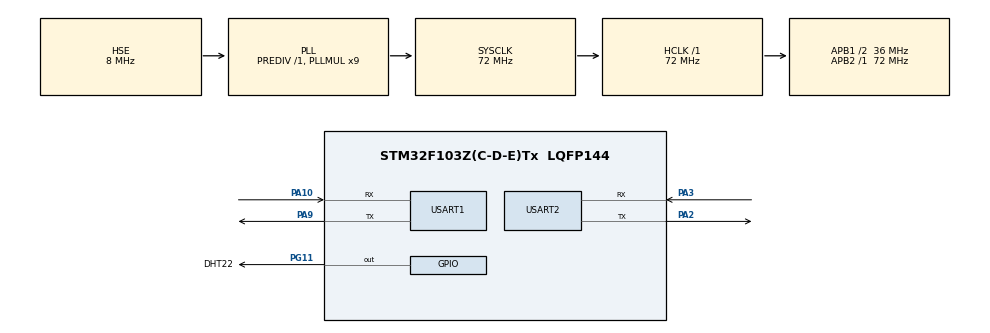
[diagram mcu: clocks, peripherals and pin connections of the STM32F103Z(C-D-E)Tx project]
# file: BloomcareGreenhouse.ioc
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Dma.Request0=USART2_RX
Dma.Request1=USART2_TX
Dma.USART2_RX.0.Direction=DMA_PERIPH_TO_MEMORY
Dma.USART2_RX.0.Instance=DMA1_Channel6
Dma.USART2_RX.0.MemDataAlignment=DMA_MDATAALIGN_BYTE
Dma.USART2_RX.0.MemInc=DMA_MINC_ENABLE
Dma.USART2_RX.0.Mode=DMA_CIRCULAR
Dma.USART2_RX.0.PeriphDataAlignment=DMA_PDATAALIGN_BYTE
Dma.USART2_RX.0.PeriphInc=DMA_PINC_DISABLE
Dma.USART2_RX.0.Priority=DMA_PRIORITY_LOW
Dma.USART2_TX.1.Direction=DMA_MEMORY_TO_PERIPH
Dma.USART2_TX.1.Instance=DMA1_Channel7
Dma.USART2_TX.1.MemDataAlignment=DMA_MDATAALIGN_BYTE
Dma.USART2_TX.1.MemInc=DMA_MINC_ENABLE
Dma.USART2_TX.1.Mode=DMA_NORMAL
Dma.USART2_TX.1.PeriphDataAlignment=DMA_PDATAALIGN_BYTE
Dma.USART2_TX.1.PeriphInc=DMA_PINC_DISABLE
Dma.USART2_TX.1.Priority=DMA_PRIORITY_LOW
Mcu.Family=STM32F1
Mcu.Name=STM32F103Z(C-D-E)Tx
Mcu.Package=LQFP144
NVIC.DMA1_Channel6_IRQn=true\:0\:0\:false\:false\:true\:false\:true\:true
NVIC.DMA1_Channel7_IRQn=true\:0\:0\:false\:false\:true\:false\:true\:true
NVIC.PriorityGroup=NVIC_PRIORITYGROUP_4
NVIC.USART2_IRQn=true\:0\:0\:false\:false\:true\:true\:true\:true
OSC_IN.Mode=HSE-External-Oscillator
OSC_IN.Signal=RCC_OSC_IN
OSC_OUT.Mode=HSE-External-Oscillator
OSC_OUT.Signal=RCC_OSC_OUT
PA10.Mode=Asynchronous
PA10.Signal=USART1_RX
PA2.Mode=Asynchronous
PA2.Signal=USART2_TX
PA3.Mode=Asynchronous
PA3.Signal=USART2_RX
PA9.Mode=Asynchronous
PA9.Signal=USART1_TX
PG11.GPIO_Label=DHT22
PG11.PinState=GPIO_PIN_SET
PG11.Signal=GPIO_Output
ProjectManager.HeapSize=0x200
ProjectManager.StackSize=0x400
ProjectManager.TargetToolchain=MDK-ARM V5.32
RCC.AHBFreq_Value=72000000
RCC.APB1CLKDivider=RCC_HCLK_DIV2
RCC.APB1Freq_Value=36000000
RCC.APB1TimFreq_Value=72000000
RCC.APB2Freq_Value=72000000
RCC.APB2TimFreq_Value=72000000
RCC.HCLKFreq_Value=72000000
RCC.PLLMUL=RCC_PLL_MUL9
RCC.PLLSourceVirtual=RCC_PLLSOURCE_HSE
RCC.SYSCLKFreq_VALUE=72000000
RCC.SYSCLKSource=RCC_SYSCLKSOURCE_PLLCLK
RCC.USBFreq_Value=72000000
TIM2.Prescaler=71
USART1.VirtualMode=VM_ASYNC
USART2.VirtualMode=VM_ASYNC
VP_SYS_VS_ND.Mode=No_Debug
VP_TIM2_VS_ClockSourceINT.Mode=Internal
board=custom

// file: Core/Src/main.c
/* USER CODE BEGIN Header */
/**
  ******************************************************************************
  * @file           : main.c
  * @brief          : Main program body
  ******************************************************************************
  * @attention
  *
  * Copyright (c) 2026 STMicroelectronics.
  * All rights reserved.
  *
  * This software is licensed under terms that can be found in the LICENSE file
  * in the root directory of this software component.
  * If no LICENSE file comes with this software, it is provided AS-IS.
  *
  ******************************************************************************
  */
/* USER CODE END Header */
#include "main.h"

/* USER CODE BEGIN Includes */
#include "bsp_delay.h"     /* BSP    : TIM2 microsecond delay, USART1 console */
#include "bsp_uart.h"      /* BSP    : USART2 link transport, DMA ring + IDLE */
#include "dev_manager.h"   /* Device : sensor / actuator table                */
#include "task_comm.h"     /* Tasks  : link protocol service                  */
#include "task_sensor.h"   /* Tasks  : acquisition and reporting              */
#include "task_control.h"  /* Tasks  : command execution                      */
#include <stdio.h>
/* USER CODE END Includes */

TIM_HandleTypeDef htim2;

UART_HandleTypeDef huart1;
UART_HandleTypeDef huart2;
DMA_HandleTypeDef hdma_usart2_rx;
DMA_HandleTypeDef hdma_usart2_tx;

void SystemClock_Config(void);
static void MX_GPIO_Init(void);
static void MX_DMA_Init(void);
static void MX_USART1_UART_Init(void);
static void MX_TIM2_Init(void);
static void MX_USART2_UART_Init(void);

/* USER CODE BEGIN 0 */
/* ------------------------------------------------------------------
   The application logic lives in the Tasks/ layer now:
     Tasks/task_comm.c    - link protocol service and debug counters
     Tasks/task_sensor.c  - sensor acquisition and reporting
     Tasks/task_control.c - command execution on the actuators
   main.c stays the thin CubeMX shell: start the layers, then poll them.
   ------------------------------------------------------------------ */
/* USER CODE END 0 */

int main(void)
{

  /* MCU Configuration--------------------------------------------------------*/

  /* Reset of all peripherals, Initializes the Flash interface and the Systick. */
  HAL_Init();

  /* Configure the system clock */
  SystemClock_Config();

  /* Initialize all configured peripherals */
  MX_GPIO_Init();
  MX_DMA_Init();
  MX_USART1_UART_Init();
  MX_TIM2_Init();
  MX_USART2_UART_Init();
  /* USER CODE BEGIN 2 */
  /* Start the layers bottom up: board -> devices -> tasks. */
  BSP_Delay_Init();                  /* TIM2 as free running 1us counter     */
  BSP_Uart_Init();                   /* USART1 console, printf goes here     */
  (void)Dev_Manager_Init();          /* open every device of the table       */
  Dev_Manager_List();                /* print what got registered            */
  Task_Sensor_Init();                /* acquisition timers                   */
  Task_Control_Init();               /* CONTROL command handling             */
  Task_Comm_Init();                  /* protocol, USART2 DMA ring + IDLE     */
  printf("[BOOT] USART1 115200 8N1 ready\r\n");
/* USER CODE END 2 */

  /* Infinite loop */
  /* USER CODE BEGIN WHILE */
  uint32_t now;

  while (1)
  {
    now = HAL_GetTick();

    Task_Comm_Poll(now);           /* parse RX, answer CONTROL, resend TX    */
    Task_Sensor_Poll(now);         /* sample the devices and report them     */
    /* USER CODE END WHILE */

  }
}

void SystemClock_Config(void)
{
  RCC_OscInitTypeDef RCC_OscInitStruct = {0};
  RCC_ClkInitTypeDef RCC_ClkInitStruct = {0};

  /** Initializes the RCC Oscillators according to the specified parameters
  * in the RCC_OscInitTypeDef structure.
  */
  RCC_OscInitStruct.OscillatorType = RCC_OSCILLATORTYPE_HSE;
  RCC_OscInitStruct.HSEState = RCC_HSE_ON;
  RCC_OscInitStruct.HSEPredivValue = RCC_HSE_PREDIV_DIV1;
  RCC_OscInitStruct.HSIState = RCC_HSI_ON;
  RCC_OscInitStruct.PLL.PLLState = RCC_PLL_ON;
  RCC_OscInitStruct.PLL.PLLSource = RCC_PLLSOURCE_HSE;
  RCC_OscInitStruct.PLL.PLLMUL = RCC_PLL_MUL9;
  if (HAL_RCC_OscConfig(&RCC_OscInitStruct) != HAL_OK)
  {
    Error_Handler();
  }

  /** Initializes the CPU, AHB and APB buses clocks
  */
  RCC_ClkInitStruct.ClockType = RCC_CLOCKTYPE_HCLK|RCC_CLOCKTYPE_SYSCLK
                              |RCC_CLOCKTYPE_PCLK1|RCC_CLOCKTYPE_PCLK2;
  RCC_ClkInitStruct.SYSCLKSource = RCC_SYSCLKSOURCE_PLLCLK;
  RCC_ClkInitStruct.AHBCLKDivider = RCC_SYSCLK_DIV1;
  RCC_ClkInitStruct.APB1CLKDivider = RCC_HCLK_DIV2;
  RCC_ClkInitStruct.APB2CLKDivider = RCC_HCLK_DIV1;

  if (HAL_RCC_ClockConfig(&RCC_ClkInitStruct, FLASH_LATENCY_2) != HAL_OK)
  {
    Error_Handler();
  }
}

static void MX_TIM2_Init(void)
{

  TIM_ClockConfigTypeDef sClockSourceConfig = {0};
  TIM_MasterConfigTypeDef sMasterConfig = {0};

  htim2.Instance = TIM2;
  htim2.Init.Prescaler = 71;
  htim2.Init.CounterMode = TIM_COUNTERMODE_UP;
  htim2.Init.Period = 65535;
  htim2.Init.ClockDivision = TIM_CLOCKDIVISION_DIV1;
  htim2.Init.AutoReloadPreload = TIM_AUTORELOAD_PRELOAD_DISABLE;
  if (HAL_TIM_Base_Init(&htim2) != HAL_OK)
  {
    Error_Handler();
  }
  sClockSourceConfig.ClockSource = TIM_CLOCKSOURCE_INTERNAL;
  if (HAL_TIM_ConfigClockSource(&htim2, &sClockSourceConfig) != HAL_OK)
  {
    Error_Handler();
  }
  sMasterConfig.MasterOutputTrigger = TIM_TRGO_RESET;
  sMasterConfig.MasterSlaveMode = TIM_MASTERSLAVEMODE_DISABLE;
  if (HAL_TIMEx_MasterConfigSynchronization(&htim2, &sMasterConfig) != HAL_OK)
  {
    Error_Handler();
  }

}

static void MX_USART1_UART_Init(void)
{

  huart1.Instance = USART1;
  huart1.Init.BaudRate = 115200;
  huart1.Init.WordLength = UART_WORDLENGTH_8B;
  huart1.Init.StopBits = UART_STOPBITS_1;
  huart1.Init.Parity = UART_PARITY_NONE;
  huart1.Init.Mode = UART_MODE_TX_RX;
  huart1.Init.HwFlowCtl = UART_HWCONTROL_NONE;
  huart1.Init.OverSampling = UART_OVERSAMPLING_16;
  if (HAL_UART_Init(&huart1) != HAL_OK)
  {
    Error_Handler();
  }

}

static void MX_USART2_UART_Init(void)
{

  huart2.Instance = USART2;
  huart2.Init.BaudRate = 115200;
  huart2.Init.WordLength = UART_WORDLENGTH_8B;
  huart2.Init.StopBits = UART_STOPBITS_1;
  huart2.Init.Parity = UART_PARITY_NONE;
  huart2.Init.Mode = UART_MODE_TX_RX;
  huart2.Init.HwFlowCtl = UART_HWCONTROL_NONE;
  huart2.Init.OverSampling = UART_OVERSAMPLING_16;
  if (HAL_UART_Init(&huart2) != HAL_OK)
  {
    Error_Handler();
  }

}

static void MX_DMA_Init(void)
{

  /* DMA controller clock enable */
  __HAL_RCC_DMA1_CLK_ENABLE();

  /* DMA interrupt init */
  /* DMA1_Channel6_IRQn interrupt configuration */
  HAL_NVIC_SetPriority(DMA1_Channel6_IRQn, 0, 0);
  HAL_NVIC_EnableIRQ(DMA1_Channel6_IRQn);
  /* DMA1_Channel7_IRQn interrupt configuration */
  HAL_NVIC_SetPriority(DMA1_Channel7_IRQn, 0, 0);
  HAL_NVIC_EnableIRQ(DMA1_Channel7_IRQn);

}

static void MX_GPIO_Init(void)
{
  GPIO_InitTypeDef GPIO_InitStruct = {0};

  /* GPIO Ports Clock Enable */
  __HAL_RCC_GPIOA_CLK_ENABLE();
  __HAL_RCC_GPIOG_CLK_ENABLE();

  /*Configure GPIO pin Output Level */
  HAL_GPIO_WritePin(DHT11_GPIO_Port, DHT11_Pin, GPIO_PIN_SET);

  /*Configure GPIO pin : DHT11_Pin */
  GPIO_InitStruct.Pin = DHT11_Pin;
  GPIO_InitStruct.Mode = GPIO_MODE_OUTPUT_PP;
  GPIO_InitStruct.Pull = GPIO_NOPULL;
  GPIO_InitStruct.Speed = GPIO_SPEED_FREQ_LOW;
  HAL_GPIO_Init(DHT11_GPIO_Port, &GPIO_InitStruct);

}

void Error_Handler(void)
{
  __disable_irq();
  while (1)
  {
  }
}
